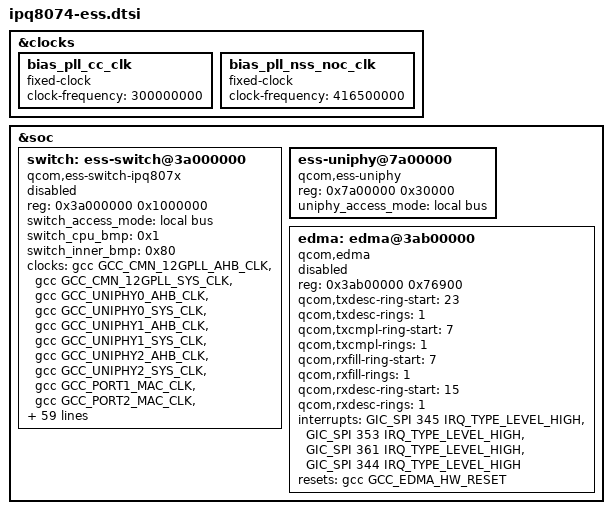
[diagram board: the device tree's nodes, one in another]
// SPDX-License-Identifier: GPL-2.0-only

&clocks {
	bias_pll_cc_clk {
		compatible = "fixed-clock";
		clock-frequency = <300000000>;
		#clock-cells = <0>;
	};

	bias_pll_nss_noc_clk {
		compatible = "fixed-clock";
		clock-frequency = <416500000>;
		#clock-cells = <0>;
	};
};

&soc {
	switch: ess-switch@3a000000 {
		compatible = "qcom,ess-switch-ipq807x";
		reg = <0x3a000000 0x1000000>;
		switch_access_mode = "local bus";
		switch_cpu_bmp = <0x1>;  /* cpu port bitmap */
		switch_inner_bmp = <0x80>; /*inner port bitmap*/
		clocks = <&gcc GCC_CMN_12GPLL_AHB_CLK>,
			 <&gcc GCC_CMN_12GPLL_SYS_CLK>,
			 <&gcc GCC_UNIPHY0_AHB_CLK>,
			 <&gcc GCC_UNIPHY0_SYS_CLK>,
			 <&gcc GCC_UNIPHY1_AHB_CLK>,
			 <&gcc GCC_UNIPHY1_SYS_CLK>,
			 <&gcc GCC_UNIPHY2_AHB_CLK>,
			 <&gcc GCC_UNIPHY2_SYS_CLK>,
			 <&gcc GCC_PORT1_MAC_CLK>,
			 <&gcc GCC_PORT2_MAC_CLK>,
			 <&gcc GCC_PORT3_MAC_CLK>,
			 <&gcc GCC_PORT4_MAC_CLK>,
			 <&gcc GCC_PORT5_MAC_CLK>,
			 <&gcc GCC_PORT6_MAC_CLK>,
			 <&gcc GCC_NSS_PPE_CLK>,
			 <&gcc GCC_NSS_PPE_CFG_CLK>,
			 <&gcc GCC_NSSNOC_PPE_CLK>,
			 <&gcc GCC_NSSNOC_PPE_CFG_CLK>,
			 <&gcc GCC_NSS_EDMA_CLK>,
			 <&gcc GCC_NSS_EDMA_CFG_CLK>,
			 <&gcc GCC_NSS_PPE_IPE_CLK>,
			 <&gcc GCC_NSS_PPE_BTQ_CLK>,
			 <&gcc GCC_MDIO_AHB_CLK>,
			 <&gcc GCC_NSS_NOC_CLK>,
			 <&gcc GCC_NSSNOC_SNOC_CLK>,
			 <&gcc GCC_MEM_NOC_NSS_AXI_CLK>,
			 <&gcc GCC_NSS_CRYPTO_CLK>,
			 <&gcc GCC_NSS_IMEM_CLK>,
			 <&gcc GCC_NSS_PTP_REF_CLK>,
			 <&gcc GCC_NSS_PORT1_RX_CLK>,
			 <&gcc GCC_NSS_PORT1_TX_CLK>,
			 <&gcc GCC_NSS_PORT2_RX_CLK>,
			 <&gcc GCC_NSS_PORT2_TX_CLK>,
			 <&gcc GCC_NSS_PORT3_RX_CLK>,
			 <&gcc GCC_NSS_PORT3_TX_CLK>,
			 <&gcc GCC_NSS_PORT4_RX_CLK>,
			 <&gcc GCC_NSS_PORT4_TX_CLK>,
			 <&gcc GCC_NSS_PORT5_RX_CLK>,
			 <&gcc GCC_NSS_PORT5_TX_CLK>,
			 <&gcc GCC_NSS_PORT6_RX_CLK>,
			 <&gcc GCC_NSS_PORT6_TX_CLK>,
			 <&gcc GCC_UNIPHY0_PORT1_RX_CLK>,
			 <&gcc GCC_UNIPHY0_PORT1_TX_CLK>,
			 <&gcc GCC_UNIPHY0_PORT2_RX_CLK>,
			 <&gcc GCC_UNIPHY0_PORT2_TX_CLK>,
			 <&gcc GCC_UNIPHY0_PORT3_RX_CLK>,
			 <&gcc GCC_UNIPHY0_PORT3_TX_CLK>,
			 <&gcc GCC_UNIPHY0_PORT4_RX_CLK>,
			 <&gcc GCC_UNIPHY0_PORT4_TX_CLK>,
			 <&gcc GCC_UNIPHY0_PORT5_RX_CLK>,
			 <&gcc GCC_UNIPHY0_PORT5_TX_CLK>,
			 <&gcc GCC_UNIPHY1_PORT5_RX_CLK>,
			 <&gcc GCC_UNIPHY1_PORT5_TX_CLK>,
			 <&gcc GCC_UNIPHY2_PORT6_RX_CLK>,
			 <&gcc GCC_UNIPHY2_PORT6_TX_CLK>,
			 <&gcc NSS_PORT5_RX_CLK_SRC>,
			 <&gcc NSS_PORT5_TX_CLK_SRC>;
		clock-names = "cmn_ahb_clk", "cmn_sys_clk",
			      "uniphy0_ahb_clk", "uniphy0_sys_clk",
			      "uniphy1_ahb_clk", "uniphy1_sys_clk",
			      "uniphy2_ahb_clk", "uniphy2_sys_clk",
			      "port1_mac_clk", "port2_mac_clk",
			      "port3_mac_clk", "port4_mac_clk",
			      "port5_mac_clk", "port6_mac_clk",
			      "nss_ppe_clk", "nss_ppe_cfg_clk",
			      "nssnoc_ppe_clk", "nssnoc_ppe_cfg_clk",
			      "nss_edma_clk", "nss_edma_cfg_clk",
			      "nss_ppe_ipe_clk", "nss_ppe_btq_clk",
			      "gcc_mdio_ahb_clk", "gcc_nss_noc_clk",
			      "gcc_nssnoc_snoc_clk",
			      "gcc_mem_noc_nss_axi_clk",
			      "gcc_nss_crypto_clk",
			      "gcc_nss_imem_clk",
			      "gcc_nss_ptp_ref_clk",
			      "nss_port1_rx_clk", "nss_port1_tx_clk",
			      "nss_port2_rx_clk", "nss_port2_tx_clk",
			      "nss_port3_rx_clk", "nss_port3_tx_clk",
			      "nss_port4_rx_clk", "nss_port4_tx_clk",
			      "nss_port5_rx_clk", "nss_port5_tx_clk",
			      "nss_port6_rx_clk", "nss_port6_tx_clk",
			      "uniphy0_port1_rx_clk",
			      "uniphy0_port1_tx_clk",
			      "uniphy0_port2_rx_clk",
			      "uniphy0_port2_tx_clk",
			      "uniphy0_port3_rx_clk",
			      "uniphy0_port3_tx_clk",
			      "uniphy0_port4_rx_clk",
			      "uniphy0_port4_tx_clk",
			      "uniphy0_port5_rx_clk",
			      "uniphy0_port5_tx_clk",
			      "uniphy1_port5_rx_clk",
			      "uniphy1_port5_tx_clk",
			      "uniphy2_port6_rx_clk",
			      "uniphy2_port6_tx_clk",
			      "nss_port5_rx_clk_src",
			      "nss_port5_tx_clk_src";
		resets = <&gcc GCC_PPE_FULL_RESET>,
			 <&gcc GCC_UNIPHY0_SOFT_RESET>,
			 <&gcc GCC_UNIPHY0_XPCS_RESET>,
			 <&gcc GCC_UNIPHY1_SOFT_RESET>,
			 <&gcc GCC_UNIPHY1_XPCS_RESET>,
			 <&gcc GCC_UNIPHY2_SOFT_RESET>,
			 <&gcc GCC_UNIPHY2_XPCS_RESET>,
			 <&gcc GCC_NSSPORT1_RESET>,
			 <&gcc GCC_NSSPORT2_RESET>,
			 <&gcc GCC_NSSPORT3_RESET>,
			 <&gcc GCC_NSSPORT4_RESET>,
			 <&gcc GCC_NSSPORT5_RESET>,
			 <&gcc GCC_NSSPORT6_RESET>;
		reset-names = "ppe_rst", "uniphy0_soft_rst",
			      "uniphy0_xpcs_rst", "uniphy1_soft_rst",
			      "uniphy1_xpcs_rst", "uniphy2_soft_rst",
			      "uniphy2_xpcs_rst", "nss_port1_rst",
			      "nss_port2_rst", "nss_port3_rst",
			      "nss_port4_rst", "nss_port5_rst",
			      "nss_port6_rst";
		mdio-bus = <&mdio>;
		status = "disabled";
	};

	ess-uniphy@7a00000 {
		compatible = "qcom,ess-uniphy";
		reg = <0x7a00000 0x30000>;
		uniphy_access_mode = "local bus";
	};

	edma: edma@3ab00000 {
		compatible = "qcom,edma";
		reg = <0x3ab00000 0x76900>;
		reg-names = "edma-reg-base";
		qcom,txdesc-ring-start = <23>;
		qcom,txdesc-rings = <1>;
		qcom,txcmpl-ring-start = <7>;
		qcom,txcmpl-rings = <1>;
		qcom,rxfill-ring-start = <7>;
		qcom,rxfill-rings = <1>;
		qcom,rxdesc-ring-start = <15>;
		qcom,rxdesc-rings = <1>;
		interrupts = <GIC_SPI 345 IRQ_TYPE_LEVEL_HIGH>,
			     <GIC_SPI 353 IRQ_TYPE_LEVEL_HIGH>,
			     <GIC_SPI 361 IRQ_TYPE_LEVEL_HIGH>,
			     <GIC_SPI 344 IRQ_TYPE_LEVEL_HIGH>;
		resets = <&gcc GCC_EDMA_HW_RESET>;
		reset-names = "edma_rst";
		status = "disabled";
	};
};
